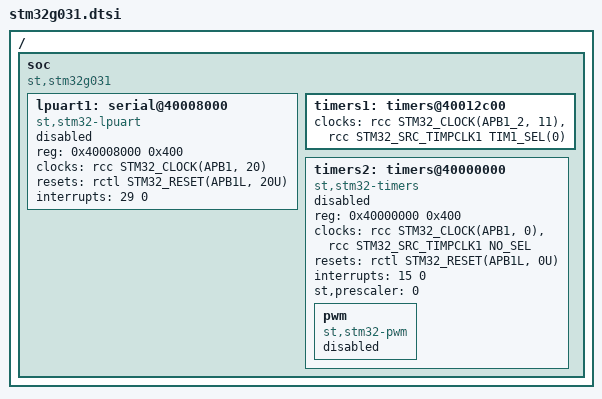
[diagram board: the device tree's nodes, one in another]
/*
 * Copyright (c) 2019 SEAL AG
 * Copyright (c) 2020 Thomas Stranger
 *
 * SPDX-License-Identifier: Apache-2.0
 */

#include <st/g0/stm32g030.dtsi>

/ {
	soc {
		compatible = "st,stm32g031", "st,stm32g0", "simple-bus";

		lpuart1: serial@40008000 {
			compatible = "st,stm32-lpuart", "st,stm32-uart";
			reg = <0x40008000 0x400>;
			clocks = <&rcc STM32_CLOCK(APB1, 20)>;
			resets = <&rctl STM32_RESET(APB1L, 20U)>;
			interrupts = <29 0>;
			status = "disabled";
		};

		timers1: timers@40012c00 {
			clocks = <&rcc STM32_CLOCK(APB1_2, 11)>,
				 <&rcc STM32_SRC_TIMPCLK1 TIM1_SEL(0)>;
		};

		timers2: timers@40000000 {
			compatible = "st,stm32-timers";
			reg = <0x40000000 0x400>;
			clocks = <&rcc STM32_CLOCK(APB1, 0)>,
				 <&rcc STM32_SRC_TIMPCLK1 NO_SEL>;
			resets = <&rctl STM32_RESET(APB1L, 0U)>;
			interrupts = <15 0>;
			interrupt-names = "global";
			st,prescaler = <0>;
			status = "disabled";

			pwm {
				compatible = "st,stm32-pwm";
				status = "disabled";
				#pwm-cells = <3>;
			};
		};
	};
};
